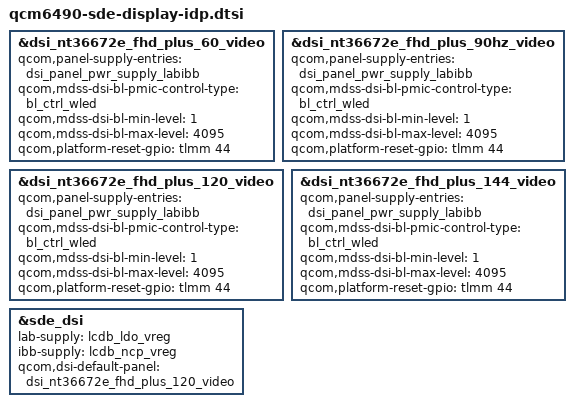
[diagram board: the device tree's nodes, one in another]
// SPDX-License-Identifier: BSD-3-Clause
/*
 * Copyright (c) 2023 Qualcomm Innovation Center, Inc. All rights reserved.
 */

#include "qcm6490-sde-display.dtsi"

&dsi_nt36672e_fhd_plus_60_video {
	qcom,panel-supply-entries = <&dsi_panel_pwr_supply_labibb>;
	qcom,mdss-dsi-bl-pmic-control-type = "bl_ctrl_wled";
	qcom,mdss-dsi-bl-min-level = <1>;
	qcom,mdss-dsi-bl-max-level = <4095>;
	qcom,platform-reset-gpio = <&tlmm 44 0>;
};

&dsi_nt36672e_fhd_plus_90hz_video {
	qcom,panel-supply-entries = <&dsi_panel_pwr_supply_labibb>;
	qcom,mdss-dsi-bl-pmic-control-type = "bl_ctrl_wled";
	qcom,mdss-dsi-bl-min-level = <1>;
	qcom,mdss-dsi-bl-max-level = <4095>;
	qcom,platform-reset-gpio = <&tlmm 44 0>;
};

&dsi_nt36672e_fhd_plus_120_video {
	qcom,panel-supply-entries = <&dsi_panel_pwr_supply_labibb>;
	qcom,mdss-dsi-bl-pmic-control-type = "bl_ctrl_wled";
	qcom,mdss-dsi-bl-min-level = <1>;
	qcom,mdss-dsi-bl-max-level = <4095>;
	qcom,platform-reset-gpio = <&tlmm 44 0>;
};

&dsi_nt36672e_fhd_plus_144_video {
	qcom,panel-supply-entries = <&dsi_panel_pwr_supply_labibb>;
	qcom,mdss-dsi-bl-pmic-control-type = "bl_ctrl_wled";
	qcom,mdss-dsi-bl-min-level = <1>;
	qcom,mdss-dsi-bl-max-level = <4095>;
	qcom,platform-reset-gpio = <&tlmm 44 0>;
};

&sde_dsi {
	lab-supply = <&lcdb_ldo_vreg>;
	ibb-supply = <&lcdb_ncp_vreg>;
	qcom,dsi-default-panel = <&dsi_nt36672e_fhd_plus_120_video>;
};
